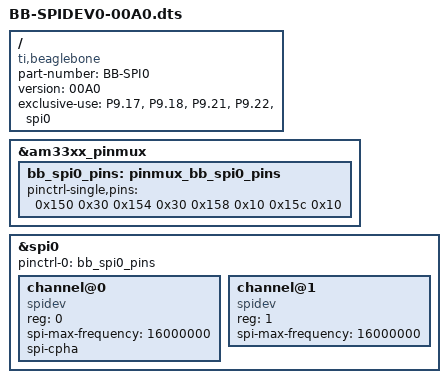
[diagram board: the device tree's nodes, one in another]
/dts-v1/;
/plugin/;

/ {
   compatible = "ti,beaglebone", "ti,beaglebone-black";

   /* identification */
   part-number = "BB-SPI0";
   version = "00A0";

   exclusive-use =
      "P9.17",
      "P9.18",
      "P9.21",
      "P9.22",
      "spi0";
	
   fragment@0 {
      target = <&am33xx_pinmux>;
      __overlay__ {
         bb_spi0_pins: pinmux_bb_spi0_pins {
            pinctrl-single,pins = <
               0x150 0x30
               0x154 0x30
               0x158 0x10
               0x15c 0x10
            >;
         };
      };
   };
   
   fragment@1 {
      target = <&spi0>;
      __overlay__ {
         #address-cells = <1>;
         #size-cells = <0>;

         status = "okay";
         pinctrl-names = "default";
         pinctrl-0 = <&bb_spi0_pins>;


         channel@0 {
            #address-cells = <1>;
            #size-cells = <0>;

            compatible = "spidev";

            reg = <0>;
            spi-max-frequency = <16000000>;
            spi-cpha;
         };


         channel@1 {
            #address-cells = <1>;
            #size-cells = <0>;

            compatible = "spidev";

            reg = <1>;
            spi-max-frequency = <16000000>;
         };
      };
   };
};
